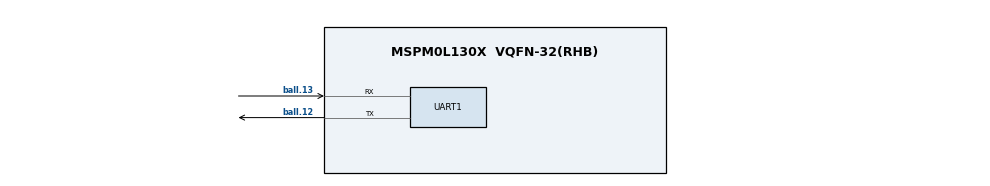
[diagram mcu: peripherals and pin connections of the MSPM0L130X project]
/**
 * @cliArgs --device "MSPM0L130X" --package "VQFN-32(RHB)" --part "Default" --product "mspm0_sdk@1.00.00.04"
 * @versions {"tool":"1.15.0+2826"}
 */

/**
 * Import the modules used in this configuration.
 */
const SYSCTL = scripting.addModule("/ti/driverlib/SYSCTL");
const UART   = scripting.addModule("/ti/driverlib/UART", {}, false);
const UART1  = UART.addInstance();

/**
 * Write custom configuration values to the imported modules.
 */

const Board = scripting.addModule("/ti/driverlib/Board", {}, false);

UART1.$name                    = "UART_0";
UART1.uartClkSrc               = "LFCLK";
UART1.ovsRate                  = "3";
UART1.enabledInterrupts        = ["RX"];
UART1.peripheral.rxPin.$assign = "ball.13";
UART1.peripheral.txPin.$assign = "ball.12";

/**
 * Pinmux solution for unlocked pins/peripherals. This ensures that minor changes to the automatic solver in a future
 * version of the tool will not impact the pinmux you originally saw.  These lines can be completely deleted in order to
 * re-solve from scratch.
 */
SYSCTL.peripheral.$suggestSolution         = "SYSCTL";
Board.peripheral.$suggestSolution          = "DEBUGSS";
Board.peripheral.swclkPin.$suggestSolution = "ball.24";
Board.peripheral.swdioPin.$suggestSolution = "ball.23";
UART1.peripheral.$suggestSolution          = "UART0";
